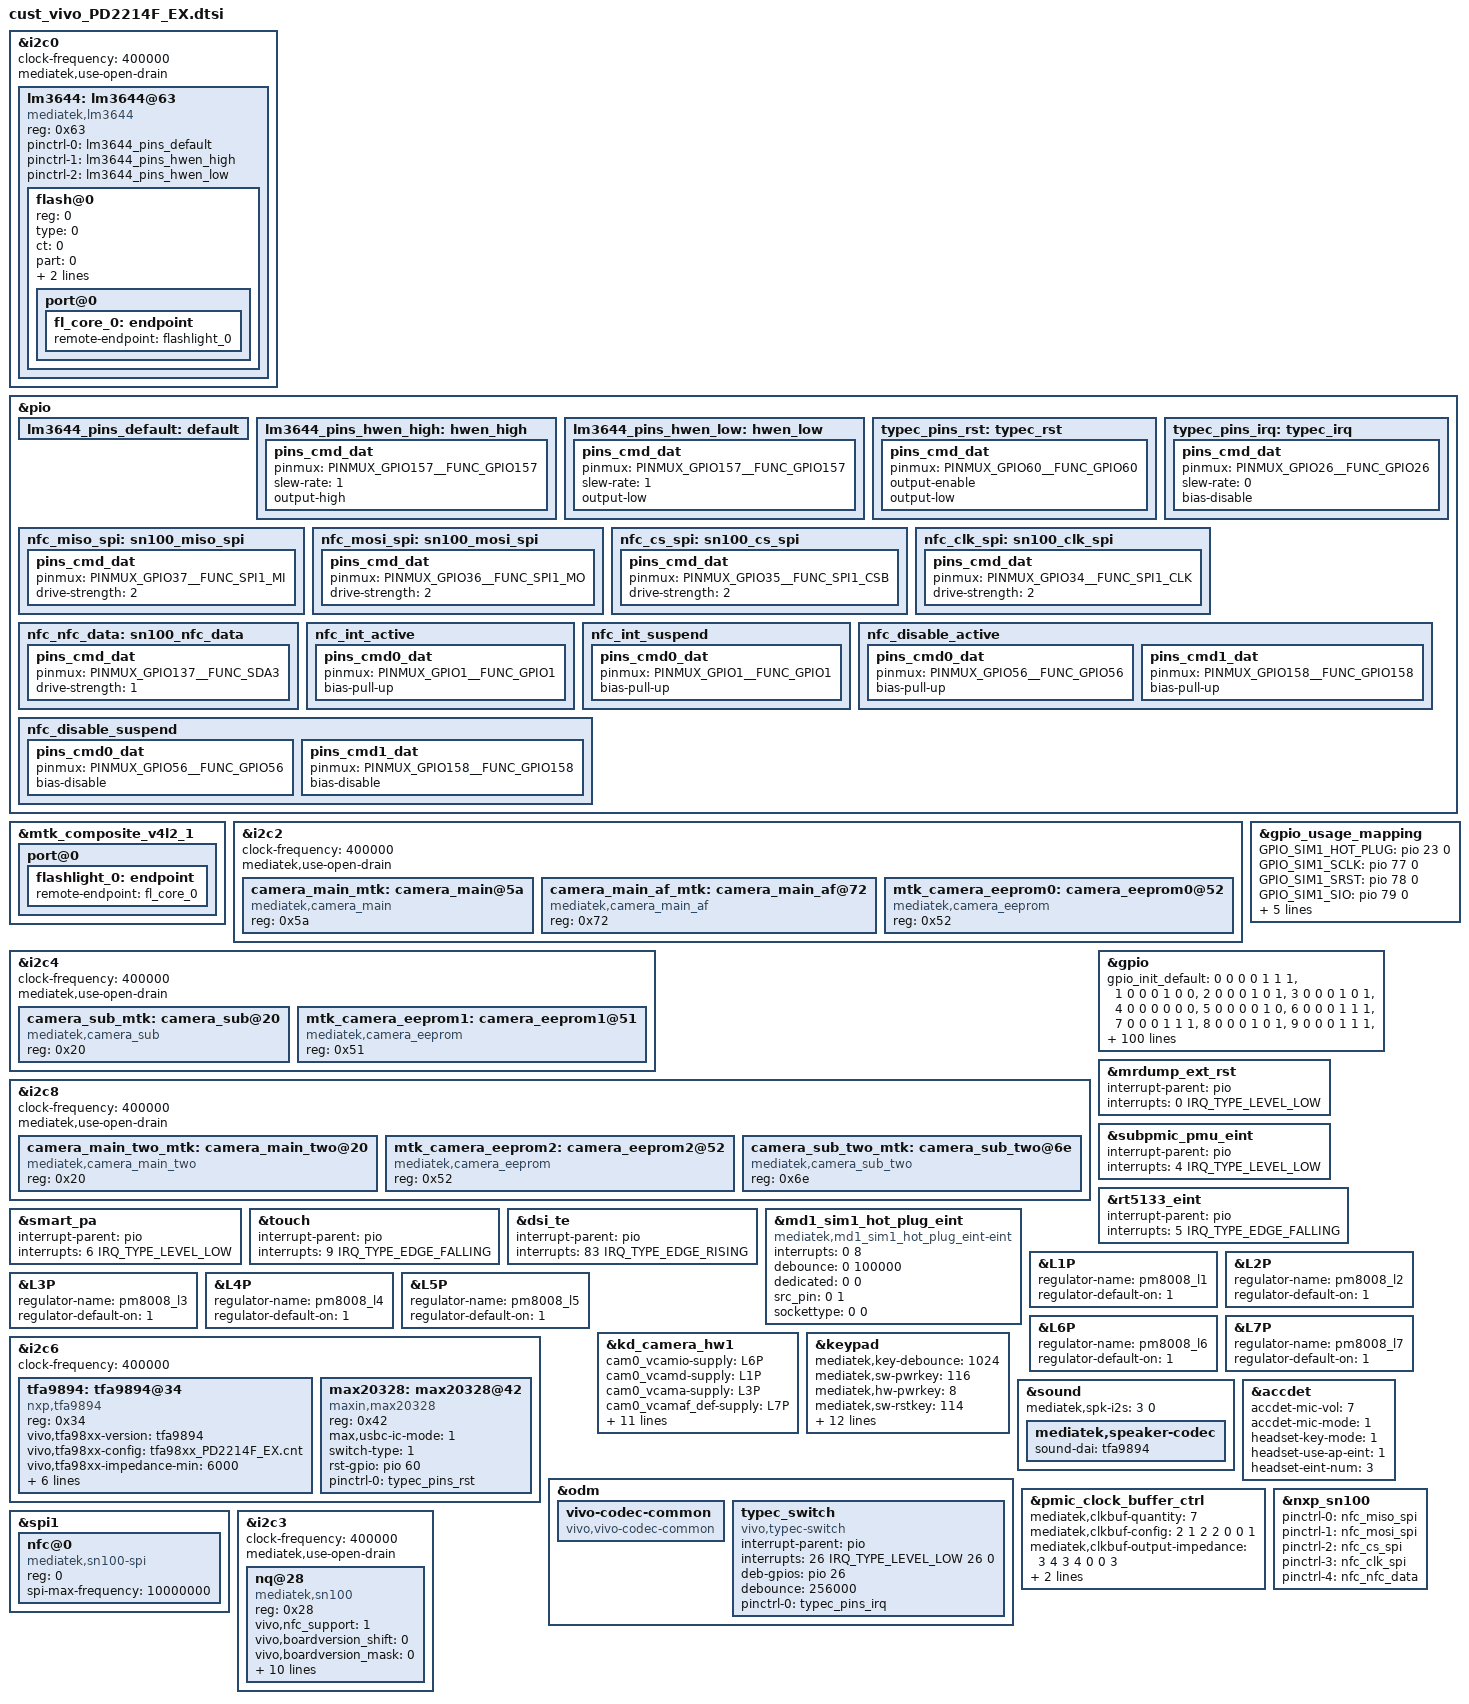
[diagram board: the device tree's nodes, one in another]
/*
 * Generated by MTK SP DrvGen Version: 3.5.160809 for MT6789.
 * 2022-04-13 16:57:22
 * Do Not Modify The File.
 * Copyright Mediatek Inc. (c) 2016.
*/

/*************************
 * ADC DTSI File
*************************/



/*************************
 * CLK_BUF DTSI File
*************************/



/*************************
 * I2C DTSI File
*************************/
&i2c0 {
	#address-cells = <1>;
	#size-cells = <0>;
	clock-frequency = <400000>;
	mediatek,use-open-drain;

	/*leizhendong add pm8008 i2c start*/
	#include "pm8008.dtsi"
	/*leizhendong add pm8008 i2c end*/
	lm3644:lm3644@63 {
		compatible = "mediatek,lm3644";
		reg = <0x63>;
		#cooling-cells = <2>;
		pinctrl-names = "default", "hwen_high", "hwen_low";
		pinctrl-0 = <&lm3644_pins_default>;
		pinctrl-1 = <&lm3644_pins_hwen_high>;
		pinctrl-2 = <&lm3644_pins_hwen_low>;
		status = "okay";
		flash@0{
			reg = <0>;
			type = <0>;
			ct = <0>;
			part = <0>;
			factory_torch_brt = <100>;  //LED0:100mA, add for factory torch test:AT+BKSG=1
			factory_flash_brt = <1050>; //LED0:1050mA, add for factory flash test:AT+FLAMP=1,1			
			port@0 {
				fl_core_0: endpoint {
					remote-endpoint = <&flashlight_0>;
				};
			};
		};
	};
};

/*************************
 * FLASHLIGHT DTSI File
*************************/
&pio {
	lm3644_pins_default: default {
	};

	lm3644_pins_hwen_high: hwen_high {
		pins_cmd_dat {
			pinmux = <PINMUX_GPIO157__FUNC_GPIO157>;
			slew-rate = <1>;
			output-high;
		};
	};

	lm3644_pins_hwen_low: hwen_low {
		pins_cmd_dat {
			pinmux = <PINMUX_GPIO157__FUNC_GPIO157>;
			slew-rate = <1>;
			output-low;
		};
	};
};
&mtk_composite_v4l2_1 {
	port@0 {
		flashlight_0: endpoint {
			remote-endpoint = <&fl_core_0>;
		};
	};
};

&i2c2 {
	#address-cells = <1>;
	#size-cells = <0>;
	clock-frequency = <400000>;
	mediatek,use-open-drain;
	camera_main_mtk:camera_main@5a {
		compatible = "mediatek,camera_main";
		reg = <0x5a>;
		status = "okay";
	};

	camera_main_af_mtk:camera_main_af@72 {
		compatible = "mediatek,camera_main_af";
		reg = <0x72>;
		status = "okay";
	};
	mtk_camera_eeprom0:camera_eeprom0@52 {
		compatible = "mediatek,camera_eeprom";
		reg = <0x52>;
		status = "okay";
	};

};

&i2c4 {
	#address-cells = <1>;
	#size-cells = <0>;
	clock-frequency = <400000>;
	mediatek,use-open-drain;
	camera_sub_mtk:camera_sub@20 {
		compatible = "mediatek,camera_sub";
		reg = <0x20>;
		status = "okay";
	};

	mtk_camera_eeprom1:camera_eeprom1@51 {
		compatible = "mediatek,camera_eeprom";
		reg = <0x51>;
		status = "okay";
	};

};

&i2c8 {
	#address-cells = <1>;
	#size-cells = <0>;
	clock-frequency = <400000>;
	mediatek,use-open-drain;
	camera_main_two_mtk:camera_main_two@20 {
		compatible = "mediatek,camera_main_two";
		reg = <0x20>;
		status = "okay";
	};

	mtk_camera_eeprom2:camera_eeprom2@52 {
		compatible = "mediatek,camera_eeprom";
		reg = <0x52>;
		status = "okay";
	};

	camera_sub_two_mtk:camera_sub_two@6e {
		compatible = "mediatek,camera_sub_two";
		reg = <0x6e>;
		status = "okay";
	};

};


/*************************
 * GPIO DTSI File
*************************/

&gpio_usage_mapping {
	GPIO_SIM1_HOT_PLUG = <&pio 23 0>;
	GPIO_SIM1_SCLK = <&pio 77 0>;
	GPIO_SIM1_SRST = <&pio 78 0>;
	GPIO_SIM1_SIO = <&pio 79 0>;
	GPIO_SIM2_SCLK = <&pio 80 0>;
	GPIO_SIM2_SRST = <&pio 81 0>;
	GPIO_SIM2_SIO = <&pio 82 0>;
	GPIO_FDD_BAND_SUPPORT_DETECT_1ST_PIN = <&pio 111 0>;
};

&gpio{
	gpio_init_default = <0 0 0 0 1 1 1>,
		<1 0 0 0 1 0 0>,
		<2 0 0 0 1 0 1>,
		<3 0 0 0 1 0 1>,
		<4 0 0 0 0 0 0>,
		<5 0 0 0 0 1 0>, /* pm8008 int */
		<6 0 0 0 1 1 1>,
		<7 0 0 0 1 1 1>,
		<8 0 0 0 1 0 1>,
		<9 0 0 0 1 1 1>,
		<10 0 0 0 1 0 1>,
		<11 0 0 0 1 1 1>,
		<12 0 1 0 1 0 1>,
		<13 6 0 0 1 0 1>,
		<14 6 0 0 1 0 0>,
		<15 0 1 0 1 0 0>,
		<16 0 1 0 1 0 0>,
		<17 0 1 1 1 1 1>, /* pm8008 en*/
		<18 0 1 0 1 0 0>,
		<19 0 1 0 1 0 0>,
		<20 0 1 0 1 0 0>,
		<21 0 1 1 1 1 1>, /* pm8008 reset*/
		<22 0 1 0 1 0 0>,
		<23 1 0 0 0 0 0>,
		<24 0 0 0 0 0 0>,
		<25 2 0 0 1 0 1>,
		<26 2 0 0 1 0 1>,
		<27 1 1 0 1 0 1>,
		<28 1 0 0 1 1 1>,
		<29 1 0 0 0 0 1>,
		<30 0 1 0 1 0 1>,
		<31 0 1 0 1 0 1>,
		<32 0 1 0 1 0 1>,
		<33 0 1 0 1 0 1>,
		<34 6 0 0 1 0 0>,
		<35 6 0 0 1 0 0>,
		<36 6 0 0 0 0 0>,
		<37 6 0 0 1 0 0>,
		<38 2 0 0 0 0 1>,
		<39 2 0 0 0 0 1>,
		<40 2 0 0 0 0 1>,
		<41 2 0 0 1 0 1>,
		<42 1 0 0 0 1 0>,
		<43 1 0 0 0 0 0>,
		<44 1 0 0 0 1 0>,
		<45 1 0 0 0 0 0>,
		<46 6 0 0 1 0 0>,
		<47 6 0 0 1 0 0>,
		<48 6 0 0 0 0 0>,
		<49 6 0 0 1 0 0>,
		<50 2 0 0 0 0 1>,
		<51 2 0 0 0 0 1>,
		<52 2 0 0 0 0 1>,
		<53 2 0 0 1 0 1>,
		<54 0 1 0 1 0 1>,
		<56 0 1 0 1 1 1>,
		<58 0 1 0 1 0 1>,
		<59 0 1 0 1 0 1>,
		<61 0 1 0 1 0 1>,
		<64 0 1 1 0 0 1>,
		<66 1 0 0 1 1 0>,
		<67 0 0 0 1 0 1>,
		<68 5 0 0 1 0 1>,
		<69 0 0 0 1 1 1>,
		<77 1 0 0 0 0 1>,
		<78 1 0 0 0 0 1>,
		<79 1 0 0 1 1 1>,
		<80 1 0 0 0 0 1>,
		<81 1 0 0 0 0 1>,
		<82 1 0 0 1 1 1>,
		<83 1 0 0 1 0 1>,
		<84 1 0 0 0 0 1>,
		<85 0 1 0 0 0 0>,
		<86 1 0 0 1 0 0>,
		<87 1 0 0 1 0 0>,
		<88 0 0 0 1 1 0>,
		<89 0 0 0 1 1 0>,
		<90 1 0 0 1 0 0>,
		<91 1 0 0 1 0 0>,
		<92 0 1 0 1 0 0>,
		<93 1 0 0 1 0 0>,
		<94 1 0 0 1 0 0>,
		<95 1 0 0 1 0 0>,
		<96 1 0 0 1 0 0>,
		<97 0 0 0 1 1 0>,
		<98 0 0 0 1 1 0>,
		<99 0 0 0 1 1 0>,
		<100 0 0 0 1 1 0>,
		<101 0 0 0 1 1 0>,
		<102 0 0 0 1 1 0>,
		<103 2 0 0 1 0 0>,
		<104 2 0 0 0 0 0>,
		<105 1 0 0 1 0 0>,
		<106 1 0 0 1 0 0>,
		<107 1 0 0 1 0 0>,
		<108 1 0 0 1 0 0>,
		<109 1 0 0 1 0 0>,
		<110 1 0 0 1 0 0>,
		<111 0 0 0 0 0 0>,
		<112 1 0 0 0 0 0>,
		<113 1 0 0 1 0 0>,
		<114 1 0 0 0 0 0>,
		<115 1 0 0 1 0 0>,
		<116 1 0 0 0 0 0>,
		<117 1 0 0 1 0 0>,
		<118 1 0 0 0 0 0>,
		<119 1 0 0 1 0 0>,
		<120 1 0 0 0 0 0>,
		<121 1 0 0 1 0 0>,
		<122 1 0 0 0 0 0>,
		<123 1 0 0 0 0 0>,
		<124 1 0 0 1 0 0>,
		<125 1 0 0 1 0 0>,
		<126 1 1 0 0 0 0>,
		<127 1 1 0 0 0 0>,
		<128 1 1 0 0 0 0>,
		<129 1 1 0 0 0 0>,
		<130 1 0 0 1 1 1>,/* i2c0 scl */
		<131 1 0 0 1 1 1>,/* i2c0 sda */
		<132 2 0 0 1 1 0>,
		<133 2 0 0 1 1 0>,
		<134 1 0 0 0 0 1>,/* i2c2 scl */
		<135 1 0 0 0 0 1>,/* i2c2 sda */
		<136 1 0 0 1 1 1>,
		<137 1 0 0 1 1 1>,
		<138 1 0 0 0 0 1>,/* i2c4 scl */
		<139 1 0 0 0 0 1>,/* i2c4 sda */
		<140 1 0 0 1 1 1>,
		<141 1 0 0 1 1 1>,
		<142 1 0 0 1 1 1>,
		<143 1 0 0 1 1 1>,
		<144 1 0 0 1 1 1>,
		<145 1 0 0 1 1 1>,
		<146 1 0 0 0 0 1>,/* i2c8 scl */
		<147 1 0 0 0 0 1>,/* i2c8 sda */
		<148 2 0 0 1 1 1>,
		<149 2 0 0 1 1 1>,
		<150 0 1 0 1 0 1>,
		<151 0 1 1 1 0 1>,
		<152 0 1 0 1 0 1>,
		<153 0 0 0 1 0 1>,
		<154 0 1 0 1 0 1>,/* flash TORCH */
		<155 0 1 0 1 0 1>,/* flash STROB */
		<156 0 1 0 1 0 1>,
		<157 0 1 0 1 0 1>,/* flash_EN */
		<158 0 1 0 1 0 1>,
		<159 0 1 0 1 0 0>,
		<160 1 0 0 0 0 1>,
		<161 1 0 0 0 0 1>,
		<162 1 0 0 0 0 1>,
		<163 1 0 0 1 0 1>,
		<164 1 0 0 0 0 1>,
		<165 1 0 0 0 0 1>,
		<166 1 0 0 0 0 1>,
		<167 1 0 0 1 0 1>,
		<168 1 0 0 0 0 0>,
		<169 1 0 0 0 0 1>,
		<170 1 0 0 0 0 1>,
		<171 1 0 0 0 0 1>,
		<172 1 0 0 0 0 1>,
		<173 1 0 0 1 0 1>,
		<174 1 0 0 1 0 1>,
		<175 1 0 0 1 0 1>,
		<176 1 0 0 1 0 1>,
		<177 0 0 0 1 0 0>,
		<178 0 0 0 1 0 0>,
		<179 0 0 0 1 0 0>,
		<180 0 0 0 1 0 0>,
		<181 0 0 0 1 0 0>,
		<182 0 0 0 1 0 0>,
		<183 0 0 0 1 0 0>,
		<184 0 0 0 1 0 0>,
		<185 0 0 0 1 0 0>,
		<186 1 0 0 1 1 1>,
		<187 1 0 0 1 1 1>,
		<188 0 0 0 1 0 0>,
		<189 0 0 0 1 0 0>,
		<190 0 0 0 1 0 0>,
		<191 0 0 0 1 0 0>,
		<192 0 0 0 1 0 0>,
		<193 0 0 0 1 0 0>,
		<194 0 0 0 1 0 0>,
		<195 0 0 0 1 0 0>,
		<196 0 0 0 1 0 0>,
		<197 0 0 0 1 0 0>,
		<198 0 0 0 1 0 0>,
		<199 0 0 0 1 0 0>,
		<200 0 0 0 1 0 0>,
		<201 0 0 0 1 0 0>,
		<202 0 0 0 1 0 0>,
		<203 0 0 0 1 0 0>,
		<204 0 0 0 1 0 0>,
		<205 0 0 0 1 0 0>,
		<206 0 0 0 1 0 0>,
		<207 0 0 0 1 0 0>,
		<208 0 0 0 1 0 0>,
		<209 0 0 0 1 0 0>,
		<210 0 0 0 1 0 0>,
		<211 0 0 0 1 0 0>,
		<212 0 0 0 1 0 0>,
		<213 0 0 0 1 0 0>,
		<214 0 0 0 1 0 0>,
		<215 0 0 0 1 0 0>,
		<216 0 0 0 1 0 0>,
		<217 0 0 0 1 0 0>,
		<218 0 0 0 1 0 0>,
		<219 0 0 0 1 0 0>,
		<220 0 0 0 1 0 0>,
		<221 0 0 0 1 0 0>;
};


/*************************
 * EINT DTSI File
*************************/

#include <dt-bindings/interrupt-controller/irq.h>
#include <dt-bindings/interrupt-controller/arm-gic.h>

&mrdump_ext_rst {
	interrupt-parent = <&pio>;
	interrupts = <0 IRQ_TYPE_LEVEL_LOW>;
	status = "okay";
};

&subpmic_pmu_eint {
	interrupt-parent = <&pio>;
	interrupts = <4 IRQ_TYPE_LEVEL_LOW>;
	status = "okay";
};

&rt5133_eint {
	interrupt-parent = <&pio>;
	interrupts = <5 IRQ_TYPE_EDGE_FALLING>;
	status = "okay";
};

&smart_pa {
	interrupt-parent = <&pio>;
	interrupts = <6 IRQ_TYPE_LEVEL_LOW>;
	status = "okay";
};

&touch {
	interrupt-parent = <&pio>;
	interrupts = <9 IRQ_TYPE_EDGE_FALLING>;
	status = "okay";
};

&dsi_te {
	interrupt-parent = <&pio>;
	interrupts = <83 IRQ_TYPE_EDGE_RISING>;
	status = "okay";
};



/*************************
 * MD1_EINT DTSI File
*************************/

&md1_sim1_hot_plug_eint {
	compatible = "mediatek,md1_sim1_hot_plug_eint-eint";
	interrupts = <0 8>;
	debounce = <0 100000>;
	dedicated = <0 0>;
	src_pin = <0 1>;
	sockettype = <0 0>;
	status = "okay";
};


/*************************
 * PMIC DTSI File
*************************/
/* leizhendong add pm8008 pmic start*/
&L1P {
	regulator-name = "pm8008_l1";
	regulator-default-on = <1>; /* 0:skip, 1: off, 2:on */
	status = "okay";

};

&L2P {
	regulator-name = "pm8008_l2";
	regulator-default-on = <1>; /* 0:skip, 1: off, 2:on */
	status = "okay";

};

&L3P {
	regulator-name = "pm8008_l3";
	regulator-default-on = <1>; /* 0:skip, 1: off, 2:on */
	status = "okay";

};

&L4P {
	regulator-name = "pm8008_l4";
	regulator-default-on = <1>; /* 0:skip, 1: off, 2:on */
	status = "okay";

};

&L5P {
	regulator-name = "pm8008_l5";
	regulator-default-on = <1>; /* 0:skip, 1: off, 2:on */
	status = "okay";

};

&L6P {
	regulator-name = "pm8008_l6";
	regulator-default-on = <1>; /* 0:skip, 1: off, 2:on */
	status = "okay";

};

&L7P {
	regulator-name = "pm8008_l7";
	regulator-default-on = <1>; /* 0:skip, 1: off, 2:on */
	status = "okay";
};
/* leizhendong add pm8008 pmic end*/


&kd_camera_hw1 {

	cam0_vcamio-supply = <&L6P>;
	cam0_vcamd-supply = <&L1P>;
	cam0_vcama-supply = <&L3P>;
	cam0_vcamaf_def-supply = <&L7P>;

	cam1_vcamio-supply = <&L6P>;
	cam1_vcamd-supply = <&L2P>;
	cam1_vcama-supply = <&L4P>;

	cam2_vcamio-supply = <&L6P>;
	cam2_vcama-supply = <&L5P>;

	cam3_vcamio-supply = <&L6P>;
	cam3_vcama-supply = <&L5P>;

	cam0_enable_sensor = "s5kgw3sp13pd2214_mipi_raw";
	cam1_enable_sensor = "s5kgd2sp03pd2214_mipi_raw";
	cam2_enable_sensor = "gc02m1pd2214_mipi_mono";
	cam3_enable_sensor = "gc02m1bpd2214_mipi_raw";

	status = "okay";
};

/*************************
 * POWER DTSI File
*************************/



/*************************
 * KPD DTSI File
*************************/

&keypad {
	mediatek,key-debounce = <1024>;
	mediatek,sw-pwrkey = <116>;
	mediatek,hw-pwrkey = <8>;
	mediatek,sw-rstkey  = <114>;
	mediatek,hw-rstkey = <17>;
	mediatek,use-extend-type = <0>;
	/*HW Keycode [0~71] -> Linux Keycode*/
	mediatek,hw-map-num = <72>;
	mediatek,hw-init-map = <115 0 0 0 0 0 0 0 0 0 0 0 0 0 0 0 0 0 0 0 0 0 0 0 0 0 0 0 0 0 0 0 0 0 0 0 0 0 0 0 0 0 0 0 0 0 0 0 0 0 0 0 0 0 0 0 0 0 0 0 0 0 0 0 0 0 0 0 0 0 0 0 >;
	mediatek,pwrkey-eint-gpio = <0>;
	mediatek,pwkey-gpio-din  = <0>;
	mediatek,hw-dl-key0 = <17>;
	mediatek,hw-dl-key1 = <0>;
	mediatek,hw-dl-key2 = <8>;
	mediatek,hw-recovery-key = <17>;
	mediatek,hw-factory-key = <0>;
	status = "okay";
};

/*add by vivo audio start*/
/*************************
 * AUDIO DTSI File
*************************/
&pio {
	typec_pins_rst: typec_rst {
		pins_cmd_dat {
			pinmux = <PINMUX_GPIO60__FUNC_GPIO60>;
			output-enable;
			output-low;
		};
	};
 	typec_pins_irq: typec_irq {
 		pins_cmd_dat {
 			pinmux = <PINMUX_GPIO26__FUNC_GPIO26>;
 			slew-rate = <0>;
 			bias-disable;
 		};
 	};
};
&i2c6{
	status = "okay";
	clock-frequency = <400000>;
	tfa9894: tfa9894@34 {
		status = "okay";
		compatible = "nxp,tfa9894";
		#sound-dai-cells = <0>;
		reg = <0x34>;
		vivo,tfa98xx-version = "tfa9894";
		vivo,tfa98xx-config = "tfa98xx_PD2214F_EX.cnt";
		vivo,tfa98xx-impedance-min = <6000>;
		vivo,tfa98xx-impedance-max = <10000>;
		vivo,tfa98xx-frequency-min = <600>;
		vivo,tfa98xx-frequency-max = <900>;
		vivo,tfa98xx-Qt-min = <110>;
		vivo,tfa98xx-number = <1>;
		reset-gpio = <&pio 151 0>;
	};
	max20328:max20328@42 {
		compatible = "maxin,max20328";
		reg = <0x42>;
		max,usbc-ic-mode = <1>; /* max20328: 0; fsa4480: 1 */
		switch-type = <1>; /*0:max20328, 1:FS4480*/
		rst-gpio = <&pio 60 0>;
		pinctrl-names = "typec_rst_set_state";
		pinctrl-0 = <&typec_pins_rst>;
		status = "okay";
	};
};
&sound {
	mediatek,spk-i2s = <3 0>;
	mediatek,speaker-codec {
		sound-dai = <&tfa9894>;
	};
};
&accdet{
	/* accdet micbias voltage: 0x07,2.7v;0x05,2.5v;0x02,1.9v */
	accdet-mic-vol = <7>;
	/*1:ACC mode, 2:low cost without in bias, 6:low cost with in bias*/
	accdet-mic-mode = <1>;
	/*0:ACCDET_THREE_KEY 1:ACCDET_FOUR_KEY*/
	headset-key-mode = <1>;
	/*0:ACCDET_PMIC_EINT_IRQ 1:ACCDET_AP_GPIO_EINT*/
	headset-use-ap-eint = <1>;
	headset-eint-num = <3>;

	status = "okay";
};
&odm {
	vivo-codec-common {
		compatible = "vivo,vivo-codec-common";
		status = "okay";
	};
	typec_switch: typec_switch {
		compatible = "vivo,typec-switch";
		interrupt-parent = <&pio>;
		interrupts = <26 IRQ_TYPE_LEVEL_LOW 26 0>;
		deb-gpios = <&pio 26 0>;
		debounce = <256000>;
		pinctrl-names = "typec_eint_as_int";
		pinctrl-0 = <&typec_pins_irq>;
		status = "okay";
	};
};
/*add by vivo audio end*/


&pmic_clock_buffer_ctrl {
	mediatek,clkbuf-quantity = <7>;
	mediatek,clkbuf-config = <2 1 2 2 0 0 1>;
	mediatek,clkbuf-output-impedance = <3 4 3 4 0 0 3>;
	mediatek,clkbuf-controls-for-desense = <0 4 0 4 0 0 0>;
	status = "okay";
};

/*nfc spi start*/
&spi1 {
	#address-cells = <1>;
	#size-cells = <0>;
	nfc@0 {
		compatible = "mediatek,sn100-spi";
		reg = <0>;
		spi-max-frequency = <10000000>;
		status = "okay";
	};
};

&nxp_sn100 {
    status = "okay";
	pinctrl-names = "miso_spi","mosi_spi","cs_spi","clk_spi","nfc_data";
	pinctrl-0 = <&nfc_miso_spi>;
	pinctrl-1 = <&nfc_mosi_spi>;
	pinctrl-2 = <&nfc_cs_spi>;
	pinctrl-3 = <&nfc_clk_spi>;
	pinctrl-4 = <&nfc_nfc_data>;

};

&pio {
	nfc_miso_spi: sn100_miso_spi {
		pins_cmd_dat {
			pinmux = <PINMUX_GPIO37__FUNC_SPI1_MI>;
			drive-strength = <2>;
		};
	};
	nfc_mosi_spi: sn100_mosi_spi {
		pins_cmd_dat {
			pinmux = <PINMUX_GPIO36__FUNC_SPI1_MO>;
			drive-strength = <2>;
		};
	};
	nfc_cs_spi: sn100_cs_spi {
		pins_cmd_dat {
			pinmux = <PINMUX_GPIO35__FUNC_SPI1_CSB>;
			drive-strength = <2>;
			//bias-pull-up;
		};
	};
	nfc_clk_spi: sn100_clk_spi {
		pins_cmd_dat {
			pinmux = <PINMUX_GPIO34__FUNC_SPI1_CLK>;
			drive-strength = <2>;
		};
	};
	nfc_nfc_data:sn100_nfc_data {
		pins_cmd_dat {
			pinmux = <PINMUX_GPIO137__FUNC_SDA3>;
			drive-strength = <1>;
		};
	};
};
/* nfc spi end */

/*NFC i2c3 */
&pio {
	nfc_int_active: nfc_int_active {
		pins_cmd0_dat {
			pinmux = <PINMUX_GPIO1__FUNC_GPIO1>;
			bias-pull-up;
		};
	};
	nfc_int_suspend: nfc_int_suspend {
		pins_cmd0_dat {
			pinmux = <PINMUX_GPIO1__FUNC_GPIO1>;
			bias-pull-up;
		};
	};
	nfc_disable_active: nfc_disable_active {
		pins_cmd0_dat {
			pinmux = <PINMUX_GPIO56__FUNC_GPIO56>;
			bias-pull-up;
		};
		pins_cmd1_dat {
			pinmux = <PINMUX_GPIO158__FUNC_GPIO158>;
			bias-pull-up;
		};
	};
	nfc_disable_suspend: nfc_disable_suspend {
		pins_cmd0_dat {
			pinmux = <PINMUX_GPIO56__FUNC_GPIO56>;
			bias-disable;
		};
		pins_cmd1_dat {
			pinmux = <PINMUX_GPIO158__FUNC_GPIO158>;
			bias-disable;
		};
	};


};
&i2c3 {
	status = "okay";
	#address-cells = <1>;
	#size-cells = <0>;
	clock-frequency = <400000>;
	mediatek,use-open-drain;
	nq@28 {
		compatible = "mediatek,sn100";
		reg = <0x28>;

		vivo,nfc_support = <1>;
		vivo,boardversion_shift = <0>;
		vivo,boardversion_mask = <0>;
		vivo,boardversion_num = <0>;
		vivo,boardversions = "0";

		mediatek,nq-irq = <&pio 1 0x00>;
		mediatek,nq-ven = <&pio 56 0x00>;
		mediatek,nq-firm = <&pio 158 0x00>;
		//mediatek,nq-clkreq = <&pio 194 0x00>;
		interrupt-parent = <&pio>;
		interrupts = <1 0>;
		interrupt-names = "nfc_irq";
		pinctrl-names = "nfc_active", "nfc_suspend";
		pinctrl-0 = <&nfc_int_active &nfc_disable_active>;
		pinctrl-1 = <&nfc_int_suspend &nfc_disable_suspend>;
	};
};


